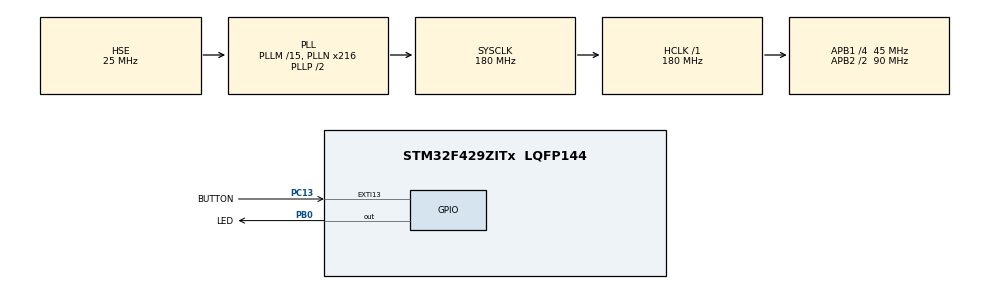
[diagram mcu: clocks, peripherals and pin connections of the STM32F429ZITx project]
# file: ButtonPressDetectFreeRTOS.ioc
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FREERTOS.Tasks01=defaultTask,24,128,StartDefaultTask,Default,NULL,Dynamic,NULL,NULL
Mcu.Family=STM32F4
Mcu.Name=STM32F429ZITx
Mcu.Package=LQFP144
NVIC.EXTI15_10_IRQn=true\:5\:0\:false\:false\:true\:true\:true\:true\:true
NVIC.PriorityGroup=NVIC_PRIORITYGROUP_4
NVIC.TIM7_IRQn=true\:15\:0\:false\:false\:true\:false\:false\:true\:true
NVIC.TimeBase=TIM7_IRQn
NVIC.TimeBaseIP=TIM7
PA13.Mode=Serial_Wire
PA13.Signal=SYS_JTMS-SWDIO
PA14.Mode=Serial_Wire
PA14.Signal=SYS_JTCK-SWCLK
PB0.GPIO_Label=LED
PB0.Signal=GPIO_Output
PC13.GPIO_Label=BUTTON
PC13.Signal=GPXTI13
PH0/OSC_IN.Mode=HSE-External-Oscillator
PH0/OSC_IN.Signal=RCC_OSC_IN
PH1/OSC_OUT.Mode=HSE-External-Oscillator
PH1/OSC_OUT.Signal=RCC_OSC_OUT
ProjectManager.HeapSize=0x200
ProjectManager.StackSize=0x400
ProjectManager.TargetToolchain=STM32CubeIDE
RCC.48MHZClocksFreq_Value=90000000
RCC.AHBFreq_Value=180000000
RCC.APB1CLKDivider=RCC_HCLK_DIV4
RCC.APB1Freq_Value=45000000
RCC.APB1TimFreq_Value=90000000
RCC.APB2CLKDivider=RCC_HCLK_DIV2
RCC.APB2Freq_Value=90000000
RCC.APB2TimFreq_Value=180000000
RCC.CortexFreq_Value=180000000
RCC.HCLKFreq_Value=180000000
RCC.HSE_VALUE=25000000
RCC.HSI_VALUE=16000000
RCC.LSE_VALUE=32768
RCC.PLLM=15
RCC.PLLN=216
RCC.PLLSourceVirtual=RCC_PLLSOURCE_HSE
RCC.SYSCLKFreq_VALUE=180000000
RCC.SYSCLKSource=RCC_SYSCLKSOURCE_PLLCLK
RCC.VCOOutputFreq_Value=360000000
VP_FREERTOS_VS_CMSIS_V2.Mode=CMSIS_V2
VP_SYS_VS_tim7.Mode=TIM7
board=custom

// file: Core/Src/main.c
/* USER CODE BEGIN Header */
/**
  ******************************************************************************
  * @file           : main.c
  * @brief          : Main program body
  ******************************************************************************
  * @attention
  *
  * Copyright (c) 2024 STMicroelectronics.
  * All rights reserved.
  *
  * This software is licensed under terms that can be found in the LICENSE file
  * in the root directory of this software component.
  * If no LICENSE file comes with this software, it is provided AS-IS.
  *
  ******************************************************************************
  */
/* USER CODE END Header */
#include "main.h"
#include "cmsis_os.h"

/* USER CODE BEGIN PTD */
struct button_trigger_data{
	uint16_t triggered_pin;
};
/* USER CODE END PTD */

/* Definitions for defaultTask */
osThreadId_t defaultTaskHandle;
const osThreadAttr_t defaultTask_attributes = {
  .name = "defaultTask",
  .stack_size = 128 * 4,
  .priority = (osPriority_t) osPriorityNormal,
};
/* USER CODE BEGIN PV */
osMessageQueueAttr_t button_trigger_queue_attr = {
		.name = "button_trigger_queue"
};
osMessageQueueId_t button_trigger_queue_handle;
/* USER CODE END PV */

void SystemClock_Config(void);
static void MX_GPIO_Init(void);
void StartDefaultTask(void *argument);

int main(void)
{

  /* MCU Configuration--------------------------------------------------------*/

  /* Reset of all peripherals, Initializes the Flash interface and the Systick. */
  HAL_Init();

  /* Configure the system clock */
  SystemClock_Config();

  /* Initialize all configured peripherals */
  MX_GPIO_Init();

  /* Init scheduler */
  osKernelInitialize();

  /* USER CODE BEGIN RTOS_QUEUES */
  /* add queues, ... */
  button_trigger_queue_handle = osMessageQueueNew(5,sizeof(struct button_trigger_data),&button_trigger_queue_attr);
  /* USER CODE END RTOS_QUEUES */

  /* Create the thread(s) */
  /* creation of defaultTask */
  defaultTaskHandle = osThreadNew(StartDefaultTask, NULL, &defaultTask_attributes);

  /* Start scheduler */
  osKernelStart();

  /* We should never get here as control is now taken by the scheduler */
  /* Infinite loop */
  while (1)
  {

  }
}

void SystemClock_Config(void)
{
  RCC_OscInitTypeDef RCC_OscInitStruct = {0};
  RCC_ClkInitTypeDef RCC_ClkInitStruct = {0};

  /** Configure the main internal regulator output voltage
  */
  __HAL_RCC_PWR_CLK_ENABLE();
  __HAL_PWR_VOLTAGESCALING_CONFIG(PWR_REGULATOR_VOLTAGE_SCALE1);

  /** Initializes the RCC Oscillators according to the specified parameters
  * in the RCC_OscInitTypeDef structure.
  */
  RCC_OscInitStruct.OscillatorType = RCC_OSCILLATORTYPE_HSE;
  RCC_OscInitStruct.HSEState = RCC_HSE_ON;
  RCC_OscInitStruct.PLL.PLLState = RCC_PLL_ON;
  RCC_OscInitStruct.PLL.PLLSource = RCC_PLLSOURCE_HSE;
  RCC_OscInitStruct.PLL.PLLM = 15;
  RCC_OscInitStruct.PLL.PLLN = 216;
  RCC_OscInitStruct.PLL.PLLP = RCC_PLLP_DIV2;
  RCC_OscInitStruct.PLL.PLLQ = 4;
  if (HAL_RCC_OscConfig(&RCC_OscInitStruct) != HAL_OK)
  {
    Error_Handler();
  }

  /** Activate the Over-Drive mode
  */
  if (HAL_PWREx_EnableOverDrive() != HAL_OK)
  {
    Error_Handler();
  }

  /** Initializes the CPU, AHB and APB buses clocks
  */
  RCC_ClkInitStruct.ClockType = RCC_CLOCKTYPE_HCLK|RCC_CLOCKTYPE_SYSCLK
                              |RCC_CLOCKTYPE_PCLK1|RCC_CLOCKTYPE_PCLK2;
  RCC_ClkInitStruct.SYSCLKSource = RCC_SYSCLKSOURCE_PLLCLK;
  RCC_ClkInitStruct.AHBCLKDivider = RCC_SYSCLK_DIV1;
  RCC_ClkInitStruct.APB1CLKDivider = RCC_HCLK_DIV4;
  RCC_ClkInitStruct.APB2CLKDivider = RCC_HCLK_DIV2;

  if (HAL_RCC_ClockConfig(&RCC_ClkInitStruct, FLASH_LATENCY_5) != HAL_OK)
  {
    Error_Handler();
  }
}

static void MX_GPIO_Init(void)
{
  GPIO_InitTypeDef GPIO_InitStruct = {0};

  /* GPIO Ports Clock Enable */
  __HAL_RCC_GPIOC_CLK_ENABLE();
  __HAL_RCC_GPIOH_CLK_ENABLE();
  __HAL_RCC_GPIOB_CLK_ENABLE();
  __HAL_RCC_GPIOA_CLK_ENABLE();

  /*Configure GPIO pin Output Level */
  HAL_GPIO_WritePin(LED_GPIO_Port, LED_Pin, GPIO_PIN_RESET);

  /*Configure GPIO pin : BUTTON_Pin */
  GPIO_InitStruct.Pin = BUTTON_Pin;
  GPIO_InitStruct.Mode = GPIO_MODE_IT_RISING;
  GPIO_InitStruct.Pull = GPIO_NOPULL;
  HAL_GPIO_Init(BUTTON_GPIO_Port, &GPIO_InitStruct);

  /*Configure GPIO pin : LED_Pin */
  GPIO_InitStruct.Pin = LED_Pin;
  GPIO_InitStruct.Mode = GPIO_MODE_OUTPUT_PP;
  GPIO_InitStruct.Pull = GPIO_NOPULL;
  GPIO_InitStruct.Speed = GPIO_SPEED_FREQ_LOW;
  HAL_GPIO_Init(LED_GPIO_Port, &GPIO_InitStruct);

  /* EXTI interrupt init*/
  HAL_NVIC_SetPriority(EXTI15_10_IRQn, 5, 0);
  HAL_NVIC_EnableIRQ(EXTI15_10_IRQn);

}

/* USER CODE BEGIN 4 */
void HAL_GPIO_EXTI_Callback(uint16_t GPIO_Pin){
	struct button_trigger_data triggered = {
			.triggered_pin = GPIO_Pin,
	};
	osMessageQueuePut(
			button_trigger_queue_handle,
			&triggered,
			0,
			0 // since we are calling this from inside a Interrupt. the timeout needs to be 0.
	);
}
/* USER CODE END 4 */

void StartDefaultTask(void *argument)
{
	/* USER CODE BEGIN 5 */
	struct button_trigger_data triggered;
	/* Infinite loop */
	for(;;)
	{
		osMessageQueueGet(button_trigger_queue_handle,&triggered,NULL,osWaitForever);
		if(triggered.triggered_pin == BUTTON_Pin){
			HAL_GPIO_TogglePin(LED_GPIO_Port, LED_Pin);
		}
	}
	/* USER CODE END 5 */
}

void HAL_TIM_PeriodElapsedCallback(TIM_HandleTypeDef *htim)
{
  if (htim->Instance == TIM7) {
    HAL_IncTick();
  }
}

void Error_Handler(void)
{
  __disable_irq();
  while (1)
  {
  }
}
